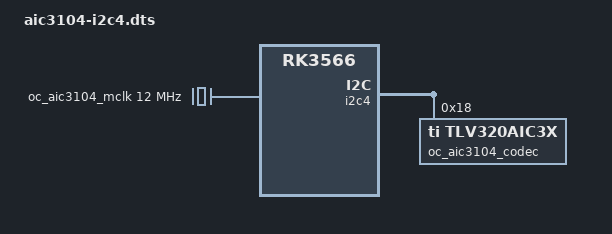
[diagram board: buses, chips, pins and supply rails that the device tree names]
/dts-v1/;
/plugin/;

/* OpenChicken Z3W-A1: adapted from the pinned OpenChicken aic3104-i2c3.dts.
 * Apply AFTER openchicken-z3w-a1. The owner confirmed a physical external
 * 12 MHz oscillator feeding codec MCLK on 2026-10-25. A fixed-clock node
 * describes that oscillator; it does not generate a clock on a header pin.
 * I2S3 BCLK/LRCLK are generated by the SBC. Its internal 12.288 MHz clock
 * is distinct from the codec's external 12 MHz input. No card-level mclk-fs.
 */
/ {
    compatible = "radxa,zero-3w", "rockchip,rk3566";

    fragment@0 {
        target-path = "/";
        __overlay__ {
            oc_aic3104_mclk: aic3104-mclk {
                compatible = "fixed-clock";
                #clock-cells = <0>;
                clock-frequency = <12000000>;
            };
        };
    };

    fragment@1 {
        target = <&i2c4>;
        __overlay__ {
            #address-cells = <1>;
            #size-cells = <0>;
            oc_aic3104_codec: codec@18 {
                compatible = "ti,tlv320aic3x";
                reg = <0x18>;
                #sound-dai-cells = <0>;
                clocks = <&oc_aic3104_mclk>;
                clock-names = "mclk";
                status = "okay";
            };
        };
    };

    fragment@2 {
        target-path = "/";
        __overlay__ {
            sound-aic3104 {
                compatible = "simple-audio-card";
                simple-audio-card,name = "aic3104";
                simple-audio-card,format = "i2s";
                simple-audio-card,bitclock-master = <&oc_aic3104_cpu>;
                simple-audio-card,frame-master = <&oc_aic3104_cpu>;
                oc_aic3104_cpu: simple-audio-card,cpu {
                    sound-dai = <&i2s3_2ch>;
                    system-clock-frequency = <12288000>;
                };
                simple-audio-card,codec {
                    sound-dai = <&oc_aic3104_codec>;
                };
            };
        };
    };
};
